# FAULT_MUX register map
Vendor: Texas Instruments
Peripheral module from a debugger description file (folder ucd3138064A).
Registers are 32-bit, access not given, no defined reset value unless marked. A register's access mark holds for its fields unless they carry their own. Offsets are as the file gives them; lines under a group give offsets from that group; [hi:lo] are bit positions; {n}, {i} and the like mark numbered series; 'fields as' and 'values as' point back to an identical list; <NAME> marks a mode.

## FAULTMUX
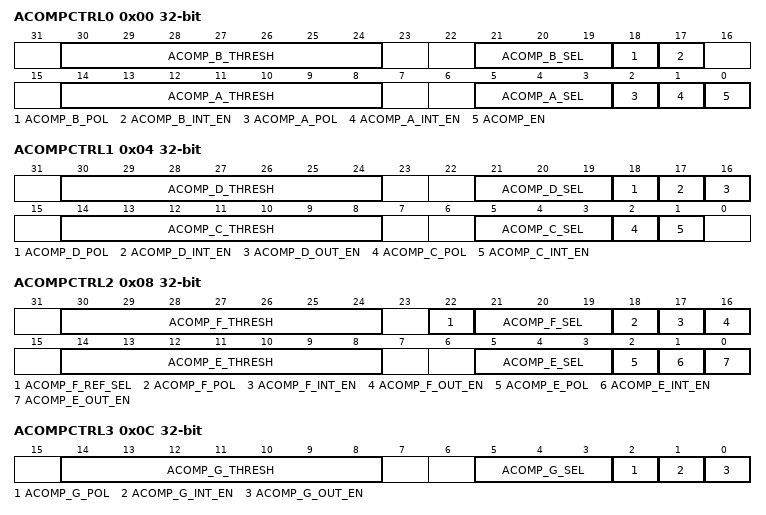
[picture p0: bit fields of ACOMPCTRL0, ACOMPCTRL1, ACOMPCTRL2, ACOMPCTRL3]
0x00 ACOMPCTRL0 — Analog Comparator Control 0 Register
  [30:24] ACOMP_B_THRESH rw — Analog Comparator B Threshold
  [21:19] ACOMP_B_SEL rw — Analog Comparator B Select
  [18] ACOMP_B_POL rw — Analog Comparator B Polarity
  [17] ACOMP_B_INT_EN rw — Analog Comparator B Interrupt Enable
  [14:8] ACOMP_A_THRESH rw — Analog Comparator A Threshold
  [5:3] ACOMP_A_SEL rw — Analog Comparator A Select
  [2] ACOMP_A_POL rw — Analog Comparator A Polarity
  [1] ACOMP_A_INT_EN rw — Analog Comparator A Interrupt Enable
  [0] ACOMP_EN rw — Analog Comparator A Enable
0x04 ACOMPCTRL1 — Analog Comparator Control 1 Register
  [30:24] ACOMP_D_THRESH rw — Analog Comparator D Threshold
  [21:19] ACOMP_D_SEL rw — Analog Comparator D Select
  [18] ACOMP_D_POL rw — Analog Comparator D Polarity
  [17] ACOMP_D_INT_EN rw — Analog Comparator D Interrupt Enable
  [16] ACOMP_D_OUT_EN rw — Analog Comparator D DAC Output Enable
  [14:8] ACOMP_C_THRESH rw — Analog Comparator C Threshold
  [5:3] ACOMP_C_SEL rw — Analog Comparator C Select
  [2] ACOMP_C_POL rw — Analog Comparator C Polarity
  [1] ACOMP_C_INT_EN rw — Analog Comparator C Interrupt Enable
0x08 ACOMPCTRL2 — Analog Comparator Control 2 Register
  [30:24] ACOMP_F_THRESH rw — [pin=64]Analog Comparator F Threshold
  [22] ACOMP_F_REF_SEL rw — [pin=64]Analog Comparator F Ref Select
  [21:19] ACOMP_F_SEL rw — [pin=64]Analog Comparator F Select
  [18] ACOMP_F_POL rw — [pin=64]Analog Comparator F Polarity
  [17] ACOMP_F_INT_EN rw — [pin=64]Analog Comparator F Interrupt Enable
  [16] ACOMP_F_OUT_EN rw — [pin=64]Analog Comparator F DAC Output Enable
  [14:8] ACOMP_E_THRESH rw — Analog Comparator E Threshold
  [5:3] ACOMP_E_SEL rw — Analog Comparator E Select
  [2] ACOMP_E_POL rw — Analog Comparator E Polarity
  [1] ACOMP_E_INT_EN rw — Analog Comparator E Interrupt Enable
  [0] ACOMP_E_OUT_EN rw — Analog Comparator E DAC Output Enable
0x0C ACOMPCTRL3 — Analog Comparator Control 3 Register
  [14:8] ACOMP_G_THRESH rw — [pin=64]Analog Comparator G Threshold
  [5:3] ACOMP_G_SEL rw — [pin=64]Analog Comparator G Select
  [2] ACOMP_G_POL rw — [pin=64]Analog Comparator G Polarity
  [1] ACOMP_G_INT_EN rw — [pin=64]Analog Comparator G Interrupt Enable
  [0] ACOMP_G_OUT_EN rw — [pin=64]Analog Comparator G DAC Output Enable
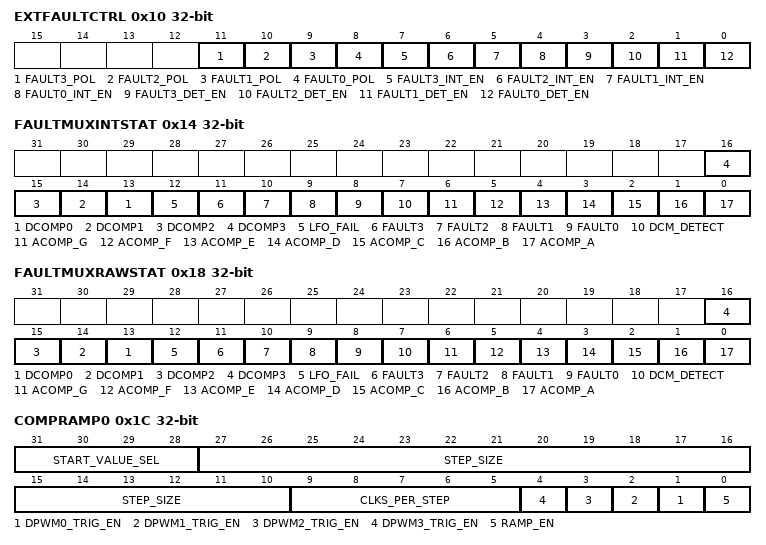
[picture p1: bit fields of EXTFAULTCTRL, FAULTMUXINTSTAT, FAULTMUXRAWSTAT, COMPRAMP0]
0x10 EXTFAULTCTRL — External Fault Control Register
  [11] FAULT3_POL rw — [pin=64]External FAULT[3] Polarity
  [10] FAULT2_POL rw — External FAULT[2] Polarity
  [9] FAULT1_POL rw — External FAULT[1] Polarity
  [8] FAULT0_POL rw — External FAULT[0] Polarity
  [7] FAULT3_INT_EN rw — [pin=64]External FAULT[3] Interrupt Enable
  [6] FAULT2_INT_EN rw — External FAULT[2] Interrupt Enable
  [5] FAULT1_INT_EN rw — External FAULT[1] Interrupt Enable
  [4] FAULT0_INT_EN rw — External FAULT[0] Interrupt Enable
  [3] FAULT3_DET_EN rw — [pin=64]External FAULT[3] Detection Enable
  [2] FAULT2_DET_EN rw — External FAULT[2] Detection Enable
  [1] FAULT1_DET_EN rw — External FAULT[1] Detection Enable
  [0] FAULT0_DET_EN rw — External FAULT[0] Detection Enable
0x14 FAULTMUXINTSTAT — Fault Mux Interrupt Status Register
  [n+13] DCOMP{n} ro (n=0..3) — Digital Comparator {n} Interrupt Status
  [12] LFO_FAIL ro — Low Frequency Oscillator Failure
  [11] FAULT3 ro — [pin=64]External FAULT[3] Detect Interrupt Status
  [10] FAULT2 ro — External FAULT[2] Detect Interrupt Status
  [9] FAULT1 ro — External FAULT[1] Detect Interrupt Status
  [8] FAULT0 ro — External FAULT[0] Detect Interrupt Status
  [7] DCM_DETECT ro — Discontinuous Conduction Mode
  [6] ACOMP_G ro — [pin=64]Analog Comparator G Interrupt Status
  [5] ACOMP_F ro — [pin=64]Analog Comparator F Interrupt Status
  [4] ACOMP_E ro — Analog Comparator E Interrupt Status
  [3] ACOMP_D ro — Analog Comparator D Interrupt Status
  [2] ACOMP_C ro — Analog Comparator C Interrupt Status
  [1] ACOMP_B ro — Analog Comparator B Interrupt Status
  [0] ACOMP_A ro — Analog Comparator A Interrupt Status
0x18 FAULTMUXRAWSTAT — Fault Mux Raw Status Register
  [n+13] DCOMP{n} ro (n=0..3) — Digital Comparator {n} Raw Status
  [12] LFO_FAIL ro — Low Frequency Oscillator Failure
  [11] FAULT3 ro — [pin=64]External FAULT[2] Detect Raw Status
  [10] FAULT2 ro — External FAULT[2] Detect Raw Status
  [9] FAULT1 ro — External FAULT[1] Detect Raw Status
  [8] FAULT0 ro — External FAULT[0] Detect Raw Status
  [7] DCM_DETECT ro — Discontinuous Conduction Mode
  [6] ACOMP_G ro — [pin=64]Analog Comparator G Raw Status
  [5] ACOMP_F ro — [pin=64]Analog Comparator F Raw Status
  [4] ACOMP_E ro — Analog Comparator E Raw Status
  [3] ACOMP_D ro — Analog Comparator D Raw Status
  [2] ACOMP_C ro — Analog Comparator C Raw Status
  [1] ACOMP_B ro — Analog Comparator B Raw Status
  [0] ACOMP_A ro — Analog Comparator A Raw Status
0x1C COMPRAMP0 rw — Comparator Ramp Control 0 Register
  [31:28] START_VALUE_SEL — Selects Ramp Start Value
  [27:10] STEP_SIZE — Comparator Ramp Step Size
  [9:5] CLKS_PER_STEP — Clocks per Ramp Step
  [n+1] DPWM{n}_TRIG_EN (n=0..3) — DPWM{n} Trigger Enable
  [0] RAMP_EN — Ramp Enable
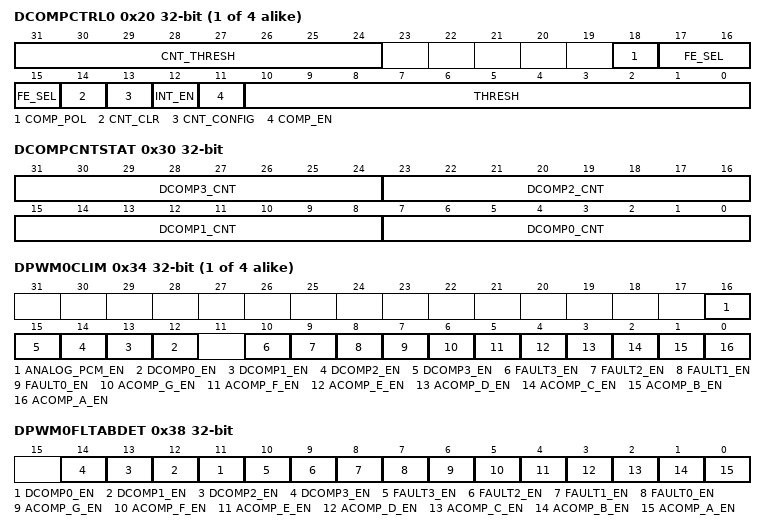
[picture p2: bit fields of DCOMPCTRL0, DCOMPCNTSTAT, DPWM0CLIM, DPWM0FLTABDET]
{0x20+4i} DCOMPCTRL{i} (i=0..3) — Digital Comparator Control {i} Register
  [31:24] CNT_THRESH rw — Digital Comparator Counter Threshold
  [18] COMP_POL rw — Digital Comparator Polarity Select
  [17:15] FE_SEL rw — Digital Comparator Front End Select
  [14] CNT_CLR rw — Digital Comparator Counter Clear
  [13] CNT_CONFIG rw — Digital Comparator Counter Configuration
  [12] INT_EN rw — Digital Comparator Interrupt Enable
  [11] COMP_EN rw — Digital Comparator Enable
  [10:0] THRESH rw — Digital Comparator Threshold
0x30 DCOMPCNTSTAT ro — Digital Comparator Counter Status Register
  [31:24] DCOMP3_CNT — Digital Comparator 3 Counter
  [23:16] DCOMP2_CNT — Digital Comparator 2 Counter
  [15:8] DCOMP1_CNT — Digital Comparator 3 Counter
  [7:0] DCOMP0_CNT — Digital Comparator 2 Counter
{0x34+0x10*i} DPWM{i}CLIM (i=0..3) — DPWM {i} Current Limit Control Register
  [16] ANALOG_PCM_EN rw — Analog Peak Current Detection Enable
  [n+12] DCOMP{n}_EN rw (n=0..3) — Digital Comparator {n} Enable
  [10] FAULT3_EN rw — [pin=64]External FAULT[3] Current Limit Enable
  [9] FAULT2_EN rw — External FAULT[2] Current Limit Enable
  [8] FAULT1_EN rw — External FAULT[1] Current Limit Enable
  [7] FAULT0_EN rw — External FAULT[0] Current Limit Enable
  [6] ACOMP_G_EN rw — [pin=64]Analog Comparator G Enable
  [5] ACOMP_F_EN rw — [pin=64]Analog Comparator F Enable
  [4] ACOMP_E_EN rw — Analog Comparator E Enable
  [3] ACOMP_D_EN rw — Analog Comparator D Enable
  [2] ACOMP_C_EN rw — Analog Comparator C Enable
  [1] ACOMP_B_EN rw — Analog Comparator B Enable
  [0] ACOMP_A_EN rw — Analog Comparator A Enable
0x38 DPWM0FLTABDET — DPWM 0 Fault AB Detection Register
  [n+11] DCOMP{n}_EN rw (n=0..3) — Digital Comparator {n} Enable
  [10] FAULT3_EN rw — [pin=64]External FAULT[2] Enable
  [9] FAULT2_EN rw — External FAULT[2] Enable
  [8] FAULT1_EN rw — External FAULT[1] Enable
  [7] FAULT0_EN rw — External FAULT[0] Enable
  [6] ACOMP_G_EN rw — [pin=64]Analog Comparator G Enable
  [5] ACOMP_F_EN rw — [pin=64]Analog Comparator F Enable
  [4] ACOMP_E_EN rw — Analog Comparator E Enable
  [3] ACOMP_D_EN rw — Analog Comparator D Enable
  [2] ACOMP_C_EN rw — Analog Comparator C Enable
  [1] ACOMP_B_EN rw — Analog Comparator B Enable
  [0] ACOMP_A_EN rw — Analog Comparator A Enable
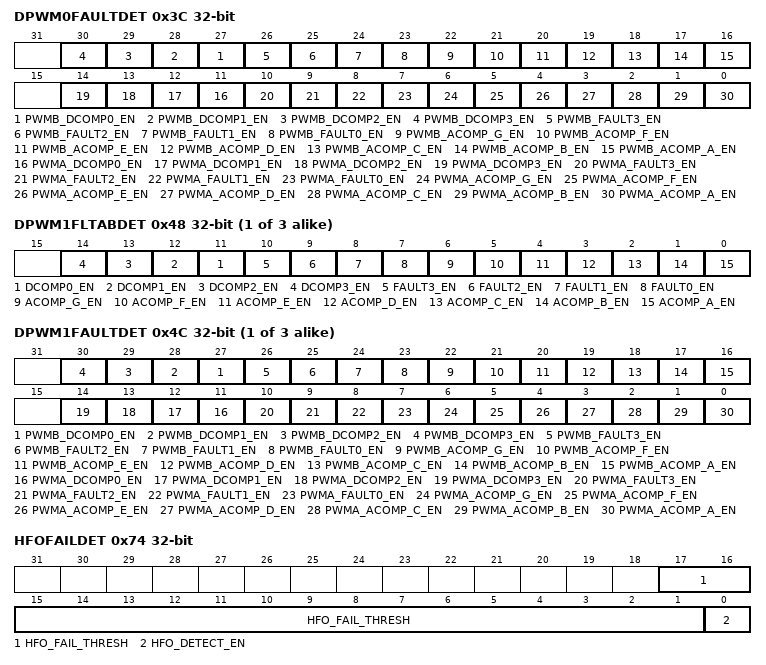
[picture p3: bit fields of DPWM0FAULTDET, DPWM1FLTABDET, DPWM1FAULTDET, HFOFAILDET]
0x3C DPWM0FAULTDET — DPWM 0 Fault Detection Register
  [n+27] PWMB_DCOMP{n}_EN rw (n=0..3) — PWM B Digital Comparator {n} Enable
  [26] PWMB_FAULT3_EN rw — [pin=64]PWM B Fault[3] Enable
  [25] PWMB_FAULT2_EN rw — PWM B Fault[2] Enable
  [24] PWMB_FAULT1_EN rw — PWM B Fault[1] Enable
  [23] PWMB_FAULT0_EN rw — PWM B Fault[0] Enable
  [22] PWMB_ACOMP_G_EN rw — [pin=64]PWM B Analog Comparator G Enable
  [21] PWMB_ACOMP_F_EN rw — [pin=64]PWM B Analog Comparator F Enable
  [20] PWMB_ACOMP_E_EN rw — PWM B Analog Comparator E Enable
  [19] PWMB_ACOMP_D_EN rw — PWM B Analog Comparator D Enable
  [18] PWMB_ACOMP_C_EN rw — PWM B Analog Comparator C Enable
  [17] PWMB_ACOMP_B_EN rw — PWM B Analog Comparator B Enable
  [16] PWMB_ACOMP_A_EN rw — PWM B Analog Comparator A Enable
  [n+11] PWMA_DCOMP{n}_EN rw (n=0..3) — PWM B Digital Comparator {n} Enable
  [10] PWMA_FAULT3_EN rw — [pin=64]PWM A Fault[2] Enable
  [9] PWMA_FAULT2_EN rw — PWM A Fault[2] Enable
  [8] PWMA_FAULT1_EN rw — PWM A Fault[1] Enable
  [7] PWMA_FAULT0_EN rw — PWM A Fault[0] Enable
  [6] PWMA_ACOMP_G_EN rw — [pin=64]PWM A Analog Comparator G Enable
  [5] PWMA_ACOMP_F_EN rw — [pin=64]PWM A Analog Comparator F Enable
  [4] PWMA_ACOMP_E_EN rw — PWM A Analog Comparator E Enable
  [3] PWMA_ACOMP_D_EN rw — PWM A Analog Comparator D Enable
  [2] PWMA_ACOMP_C_EN rw — PWM A Analog Comparator C Enable
  [1] PWMA_ACOMP_B_EN rw — PWM A Analog Comparator B Enable
  [0] PWMA_ACOMP_A_EN rw — PWM A Analog Comparator A Enable
{0x38+0x10*i} DPWM{i}FLTABDET (i=1..3) — DPWM {i} Fault AB Detection Register
  [n+11] DCOMP{n}_EN rw (n=0..3) — Digital Comparator {n} Enable
  [10] FAULT3_EN rw — [pin=64]External FAULT[3] Enable
  [9] FAULT2_EN rw — External FAULT[2] Enable
  [8] FAULT1_EN rw — External FAULT[1] Enable
  [7] FAULT0_EN rw — External FAULT[0] Enable
  [6] ACOMP_G_EN rw — [pin=64]Analog Comparator G Enable
  [5] ACOMP_F_EN rw — [pin=64]Analog Comparator F Enable
  [4] ACOMP_E_EN rw — Analog Comparator E Enable
  [3] ACOMP_D_EN rw — Analog Comparator D Enable
  [2] ACOMP_C_EN rw — Analog Comparator C Enable
  [1] ACOMP_B_EN rw — Analog Comparator B Enable
  [0] ACOMP_A_EN rw — Analog Comparator A Enable
{0x3C+0x10*i} DPWM{i}FAULTDET (i=1..3) — DPWM {i} Fault Detection Register
  [n+27] PWMB_DCOMP{n}_EN rw (n=0..3) — PWM B Digital Comparator {n} Enable
  [26] PWMB_FAULT3_EN rw — [pin=64]PWM B Fault[3] Enable
  [25] PWMB_FAULT2_EN rw — PWM B Fault[2] Enable
  [24] PWMB_FAULT1_EN rw — PWM B Fault[1] Enable
  [23] PWMB_FAULT0_EN rw — PWM B Fault[0] Enable
  [22] PWMB_ACOMP_G_EN rw — [pin=64]PWM B Analog Comparator G Enable
  [21] PWMB_ACOMP_F_EN rw — [pin=64]PWM B Analog Comparator F Enable
  [20] PWMB_ACOMP_E_EN rw — PWM B Analog Comparator E Enable
  [19] PWMB_ACOMP_D_EN rw — PWM B Analog Comparator D Enable
  [18] PWMB_ACOMP_C_EN rw — PWM B Analog Comparator C Enable
  [17] PWMB_ACOMP_B_EN rw — PWM B Analog Comparator B Enable
  [16] PWMB_ACOMP_A_EN rw — PWM B Analog Comparator A Enable
  [n+11] PWMA_DCOMP{n}_EN rw (n=0..3) — PWM B Digital Comparator {n} Enable
  [10] PWMA_FAULT3_EN rw — [pin=64]PWM A Fault[3] Enable
  [9] PWMA_FAULT2_EN rw — PWM A Fault[2] Enable
  [8] PWMA_FAULT1_EN rw — PWM A Fault[1] Enable
  [7] PWMA_FAULT0_EN rw — PWM A Fault[0] Enable
  [6] PWMA_ACOMP_G_EN rw — [pin=64]PWM A Analog Comparator G Enable
  [5] PWMA_ACOMP_F_EN rw — [pin=64]PWM A Analog Comparator F Enable
  [4] PWMA_ACOMP_E_EN rw — PWM A Analog Comparator E Enable
  [3] PWMA_ACOMP_D_EN rw — PWM A Analog Comparator D Enable
  [2] PWMA_ACOMP_C_EN rw — PWM A Analog Comparator C Enable
  [1] PWMA_ACOMP_B_EN rw — PWM A Analog Comparator B Enable
  [0] PWMA_ACOMP_A_EN rw — PWM A Analog Comparator A Enable
0x74 HFOFAILDET — High Frequency Oscillator Fail Detect Register
  [17:1] HFO_FAIL_THRESH rw — High Frequency Oscillator Fail Threshold
  [0] HFO_DETECT_EN rw — High Frequency Oscillator Fail Detect Enable
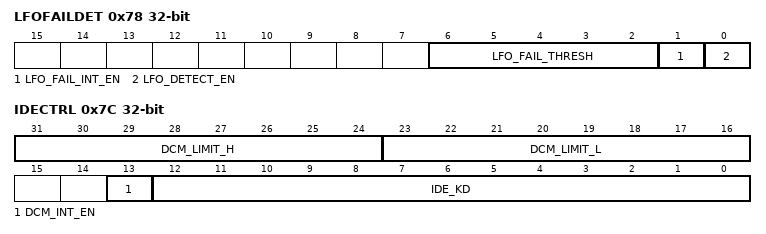
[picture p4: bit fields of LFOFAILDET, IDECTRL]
0x78 LFOFAILDET — Low Frequency Oscillator Fail Detect Register
  [6:2] LFO_FAIL_THRESH rw — Low Frequency Oscillator Fail Threshold
  [1] LFO_FAIL_INT_EN rw — Low Frequency Oscillator Fail Interrupt Enable
  [0] LFO_DETECT_EN rw — Low Frequency Oscillator Fail Detect Enable
0x7C IDECTRL — IDE Control Register
  [31:24] DCM_LIMIT_H rw — DCM Upper Hysteresis
  [23:16] DCM_LIMIT_L rw — DCM Lower Hysteresis
  [13] DCM_INT_EN rw — DCM Interrupt Enable
  [12:0] IDE_KD rw — IDE KD Factor used to calculate Db
